# MM32G0001 register map
File version: 0.9.0
CPU: CM0 r0p0, little endian, no MPU, no FPU, 2 interrupt priority bits
Registers are 32-bit, read-write, reset 0x0 unless marked. A register's access mark holds for its fields unless they carry their own. Offsets are from the block's base; [hi:lo] are bit positions; {n}, {i} and the like mark numbered series.

## TIM1 — Advanced timer
Base 0x40012C00
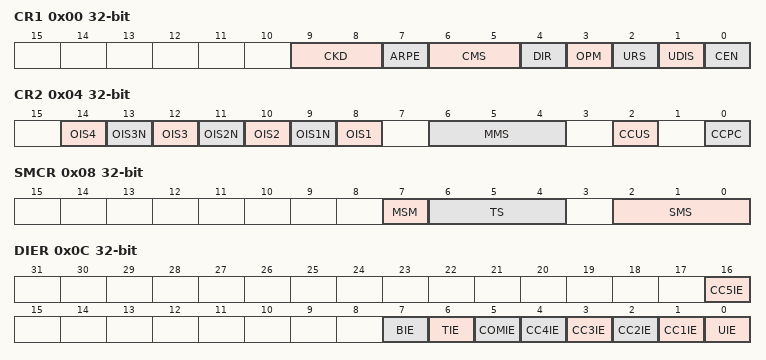
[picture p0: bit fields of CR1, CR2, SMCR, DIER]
0x00 CR1 — control register 1
  [9:8] CKD — Clock division
  [7] ARPE — Auto-reload preload enable
  [6:5] CMS — Center-aligned mode selection
  [4] DIR — Direction
  [3] OPM — One pulse mode
  [2] URS — Update request source
  [1] UDIS — Update disable
  [0] CEN — Counter enable
0x04 CR2 — control register 2
  [14] OIS4
  [13] OIS3N
  [12] OIS3
  [11] OIS2N
  [10] OIS2
  [9] OIS1N — Output Idle state 1
  [8] OIS1 — Output Idle state 1
  [6:4] MMS — Master mode selection
  [2] CCUS — compare control update selection
  [0] CCPC — compare preloaded control
0x08 SMCR — slave mode control register 1
  [7] MSM — Master/slave mode
  [6:4] TS — Trigger selection
  [2:0] SMS — Slave mode selection
0x0C DIER — DMA/Interrupt enable register
  [16] CC5IE — Compare 5 interrupt enable
  [7] BIE — Break interrupt enable
  [6] TIE — Trigger interrupt enable
  [5] COMIE — COM interrupt enable
  [n] CC{n}IE (n=1..4) — Compare {n} interrupt enable
  [0] UIE — Update interrupt enable
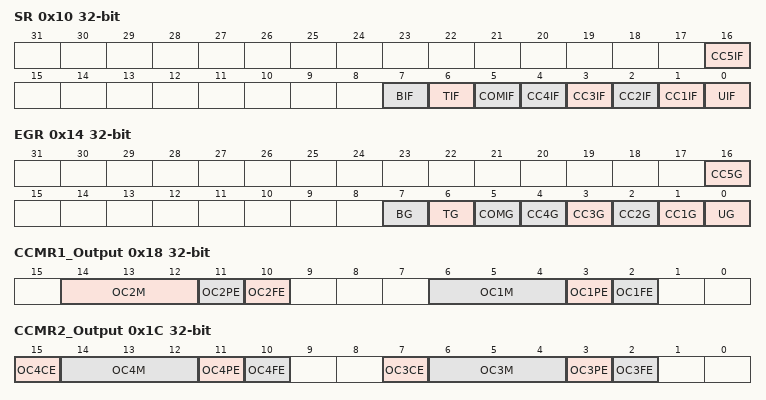
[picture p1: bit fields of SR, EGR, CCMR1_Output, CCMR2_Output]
0x10 SR — status register
  [16] CC5IF — Compare 5 interrupt flag
  [7] BIF — Break interrupt flag
  [6] TIF — Trigger interrupt flag
  [5] COMIF — COM interrupt flag
  [n] CC{n}IF (n=1..4) — Compare {n} interrupt flag
  [0] UIF — Update interrupt flag
0x14 EGR wo — event generation register
  [16] CC5G — Compare 5 generation
  [7] BG — Break generation
  [6] TG — Trigger generation
  [5] COMG — Compare control update generation
  [n] CC{n}G (n=1..4) — Compare {n} generation
  [0] UG — Update generation
0x18 CCMR1_Output — compare mode register 1 (output mode)
  [14:12] OC2M — Output compare 2 mode
  [11] OC2PE — Output compare 2 preload enable
  [10] OC2FE — Output compare 4 fast enable
  [6:4] OC1M — Output compare 1 mode
  [3] OC1PE — Output compare 1 preload enable
  [2] OC1FE — Output compare 1 fast enable
0x1C CCMR2_Output — compare mode register 2(output mode)
  [15] OC4CE — Output compare 4 clear enable
  [14:12] OC4M — Output compare 4 mode
  [11] OC4PE — Output compare 4 preload enable
  [10] OC4FE — Output compare 4 fast enable
  [7] OC3CE — Output compare 3 clear enable
  [6:4] OC3M — Output compare 3 mode
  [3] OC3PE — Output compare 3 preload enable
  [2] OC3FE — Output compare 3 fast enable
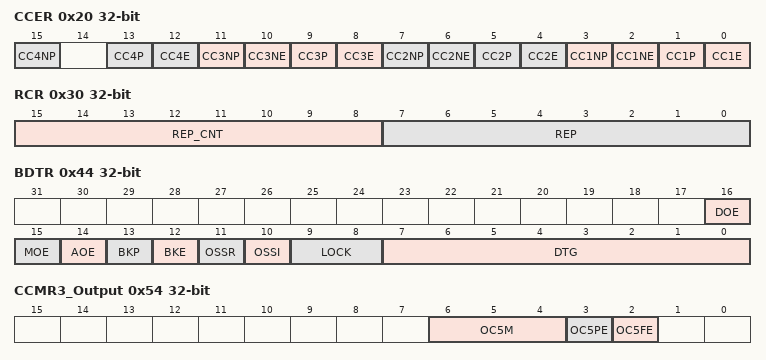
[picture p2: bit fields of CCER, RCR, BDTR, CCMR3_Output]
0x20 CCER — compare enable register
  [4n-1] CC{n}NP (n=1..4) — Compare {n} complementary output polarity
  [4n-3] CC{n}P (n=1..4) — Compare {n} output polarity
  [4n-4] CC{n}E (n=1..4) — Compare {n} output enable
  [10] CC3NE — Compare 3 complementary output enable
  [6] CC2NE — Compare 2 complementary output enable
  [2] CC1NE — Compare 1 complementary output enable
0x24 CNT — counter
  [15:0] CNT — Counter value
0x28 PSC — prescaler
  [15:0] PSC — Prescaler value
0x2C ARR — auto-reload register
  [15:0] ARR — Auto reload value
0x30 RCR — repetition counter register
  [15:8] REP_CNT — Repetition counter value of real-time writing
  [7:0] REP — Repetition counter value
{0x30+4i} CCR{i} (i=1..4) — compare register {i}
  [15:0] CCR{i} — Compare {i} value
0x44 BDTR — break and dead-time register
  [16] DOE — Direct output enable
  [15] MOE — Main output enable
  [14] AOE — Automatic output enable
  [13] BKP — Break polarity
  [12] BKE — Break enable
  [11] OSSR — Off-state selection for Run mode
  [10] OSSI — Off-state selection for Idle mode
  [9:8] LOCK — Lock configuration
  [7:0] DTG — Dead-time generator setup
0x54 CCMR3_Output — compare mode register 3 (output mode)
  [6:4] OC5M — Output compare 5 mode
  [3] OC5PE — Output compare 5 preload enable
  [2] OC5FE — Output compare 5 fast enable
0x58 CCR5 — compare register 5
  [15:0] CCR5 — Compare 5 value
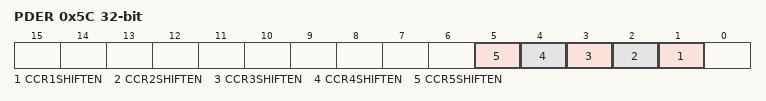
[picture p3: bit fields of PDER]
0x5C PDER — PWM/DMA repeat enable register
  [n] CCR{n}SHIFTEN (n=1..5) — CCR{n} pwm shift enable
{0x5C+4i} CCR{i}FALL (i=1..5) — pwm shift count CCR{i} register
  [15:0] CCR{i}FALL — compare value for ch{i} when counting down in PWM center-aligned mode
